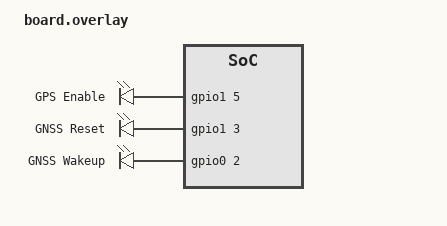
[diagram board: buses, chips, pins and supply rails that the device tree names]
/*
 * SenseCAP Solar — ZephCore overlay
 * SPDX-License-Identifier: MIT
 *
 * GPS aliases for ZephyrGPSManager. P1.05 (gps-enable alias) is shared
 * with the air530z driver's on-off-gpios (T-Echo pattern): the driver
 * powers the module at init, ZephyrGPSManager duty-cycles it after.
 */

#include "../../common/qspi-ext.dtsi"

/ {
	gps_en: gps-enable {
		compatible = "gpio-leds";
		gps_enable_pin: gps_enable {
			gpios = <&gpio1 5 GPIO_ACTIVE_HIGH>;
			label = "GPS Enable";
		};
	};

	gps_rst: gps-reset {
		compatible = "gpio-leds";
		gps_reset_pin: gps_reset {
			gpios = <&gpio1 3 GPIO_ACTIVE_HIGH>;
			label = "GNSS Reset";
		};
	};

	/* L76KB WAKEUP (schematic net GNSS_WAKEUP, P0.02; upstream's
	 * PIN_GPS_STANDBY): HIGH = run, LOW = Standby with the supply kept.
	 * The GPS manager uses it for duty-cycle standby, so a wake is a hot
	 * start; P1.05 is cut on `gps off` and System OFF. */
	gps_wake: gps-wakeup {
		compatible = "gpio-leds";
		gps_wakeup_pin: gps_wakeup {
			gpios = <&gpio0 2 GPIO_ACTIVE_HIGH>;
			label = "GNSS Wakeup";
		};
	};

	aliases {
		gps-enable = &gps_enable_pin;
		gps-reset = &gps_reset_pin;
		gps-wakeup = &gps_wakeup_pin;
	};
};
